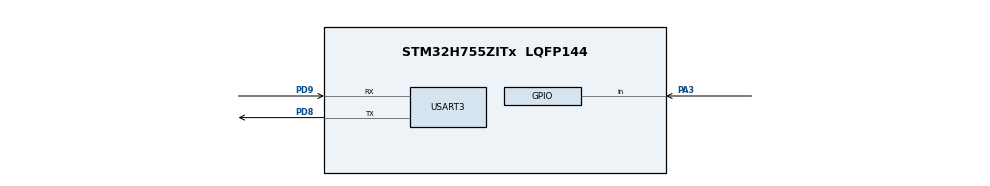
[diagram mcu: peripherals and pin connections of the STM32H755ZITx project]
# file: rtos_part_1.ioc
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CortexM4.IPs=FATFS_M4\:I,FREERTOS_M4\:I,IWDG2\:I,RCC,WWDG2\:I,DMA,BDMA,MDMA,NVIC2\:I,ETH,DEBUG,PDM2PCM_M4\:I,PWR,RESMGR_UTILITY,SYS_M4\:I,USB_DEVICE_M4\:I,USB_HOST_M4\:I,CORTEX_M4\:I,GPIO,OPENAMP_M4\:I,VREFBUF,NUCLEO-H755ZI-Q
CortexM7.IPs=FATFS_M7\:I,FREERTOS_M7\:I,IWDG1\:I,RCC\:I,WWDG1\:I,DMA\:I,BDMA\:I,MDMA\:I,NVIC1\:I,ETH\:I,USB_OTG_FS\:I,USB_OTG_FS1\:I,SYS\:I,CORTEX_M7\:I,DEBUG\:I,PDM2PCM_M7\:I,PWR\:I,RESMGR_UTILITY\:I,USB_DEVICE_M7\:I,USB_HOST_M7\:I,GPIO\:I,OPENAMP_M7\:I,VREFBUF\:I,NUCLEO-H755ZI-Q\:I,TIM6\:I,USART3\:I
CortexM7.Pins=PA3
FREERTOS_M7.Queues01=message_q,10,uint32_t,0,Dynamic,NULL,NULL
FREERTOS_M7.Tasks01=Task_1,24,128,Start_Task_1,Default,NULL,Dynamic,NULL,NULL;Task_2,24,128,Start_Task_2,Default,NULL,Dynamic,NULL,NULL;Task_3_Rx,32,512,Rx_task,Default,NULL,Dynamic,NULL,NULL
FREERTOS_M7.configUSE_NEWLIB_REENTRANT=1
Mcu.Family=STM32H7
Mcu.Name=STM32H755ZITx
Mcu.Package=LQFP144
NVIC1.PriorityGroup=NVIC_PRIORITYGROUP_4
NVIC1.TIM6_DAC_IRQn=true\:15\:0\:false\:false\:true\:false\:false\:true\:true
NVIC1.TimeBase=TIM6_DAC_IRQn
NVIC1.TimeBaseIP=TIM6
NVIC2.PriorityGroup=NVIC_PRIORITYGROUP_4
PA3.GPIO_PuPd=GPIO_PULLUP
PA3.PinAttribute=CortexM7
PA3.Signal=GPIO_Input
PD8.Mode=Asynchronous
PD8.PinAttribute=CortexM7
PD8.Signal=USART3_TX
PD9.Mode=Asynchronous
PD9.PinAttribute=CortexM7
PD9.Signal=USART3_RX
ProjectManager.HeapSize=M4-0x200,M7-0x200
ProjectManager.StackSize=M4-0x400,M7-0x400
ProjectManager.TargetToolchain=STM32CubeIDE
RCC.ADCFreq_Value=129000000
RCC.APB1Freq_Value=100000000
RCC.APB2Freq_Value=100000000
RCC.APB3Freq_Value=100000000
RCC.APB4Freq_Value=100000000
RCC.CortexFreq_Value=400000000
RCC.D1PPRE=RCC_APB3_DIV2
RCC.D2PPRE1=RCC_APB1_DIV2
RCC.D2PPRE2=RCC_APB2_DIV2
RCC.D3PPRE=RCC_APB4_DIV2
RCC.DIVM1=4
RCC.DIVN1=50
RCC.DIVQ1=5
RCC.HCLKFreq_Value=200000000
RCC.HPRE=RCC_HCLK_DIV2
RCC.PLL2FRACN=0
RCC.PLL3FRACN=0
RCC.PLLFRACN=0
RCC.SYSCLKFreq_VALUE=400000000
RCC.SYSCLKSource=RCC_SYSCLKSOURCE_PLLCLK
RCC.SupplySource=PWR_DIRECT_SMPS_SUPPLY
RCC.USBFreq_Value=160000000
USART3.VirtualMode-Asynchronous=VM_ASYNC
VP_FREERTOS_M7_VS_CMSIS_V2.Mode=CMSIS_V2
VP_SYS_M4_VS_Systick.Mode=SysTick
VP_SYS_VS_tim6.Mode=TIM6
board=NUCLEO-H755ZI-Q

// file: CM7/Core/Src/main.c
/* USER CODE BEGIN Header */
/**
  ******************************************************************************
  * @file           : main.c
  * @brief          : Main program body
  ******************************************************************************
  * @attention
  *
  * Copyright (c) 2026 STMicroelectronics.
  * All rights reserved.
  *
  * This software is licensed under terms that can be found in the LICENSE file
  * in the root directory of this software component.
  * If no LICENSE file comes with this software, it is provided AS-IS.
  *
  ******************************************************************************
  */
/* USER CODE END Header */
#include "main.h"
#include "FreeRTOS.h"
#include "cmsis_os2.h"
#include "Stdio.h"

/* USER CODE BEGIN PD */

/* DUAL_CORE_BOOT_SYNC_SEQUENCE: Define for dual core boot synchronization    */
/*                             demonstration code based on hardware semaphore */
/* This define is present in both CM7/CM4 projects                            */
/* To comment when developping/debugging on a single core                     */
#define DUAL_CORE_BOOT_SYNC_SEQUENCE

#if defined(DUAL_CORE_BOOT_SYNC_SEQUENCE)
#ifndef HSEM_ID_0
#define HSEM_ID_0 (0U) /* HW semaphore 0*/
#endif
#endif /* DUAL_CORE_BOOT_SYNC_SEQUENCE */

/* USER CODE END PD */

UART_HandleTypeDef huart3;

/* Definitions for Task_1 */
osThreadId_t Task_1Handle;
const osThreadAttr_t Task_1_attributes = {
  .name = "Task_1",
  .stack_size = 128 * 4,
  .priority = (osPriority_t) osPriorityNormal,
};
/* Definitions for Task_2 */
osThreadId_t Task_2Handle;
const osThreadAttr_t Task_2_attributes = {
  .name = "Task_2",
  .stack_size = 128 * 4,
  .priority = (osPriority_t) osPriorityNormal,
};
/* Definitions for Task_3_Rx */
osThreadId_t Task_3_RxHandle;
const osThreadAttr_t Task_3_Rx_attributes = {
  .name = "Task_3_Rx",
  .stack_size = 512 * 4,
  .priority = (osPriority_t) osPriorityAboveNormal,
};
/* Definitions for message_q */
osMessageQueueId_t message_qHandle;
const osMessageQueueAttr_t message_q_attributes = {
  .name = "message_q"
};

void SystemClock_Config(void);
static void MX_GPIO_Init(void);
static void MX_USART3_UART_Init(void);
void Start_Task_1(void *argument);
void Start_Task_2(void *argument);
void Rx_task(void *argument);

/* USER CODE BEGIN 0 */
typedef struct {
	uint32_t timestamp;
	uint32_t event_id;
}message_q_t;
int _io_putchar(uint8_t ch){
	HAL_UART_Transmit(&huart3,&ch, 1, HAL_MAX_DELAY);
	return ch;
}
 int _write(int file, char *ptr, int len)
{
  (void)file;
  int DataIdx;

  for (DataIdx = 0; DataIdx < len; DataIdx++)
  {
	  _io_putchar(*ptr++);
  }
  return len;
}

/* USER CODE END 0 */

int main(void)
{

/* USER CODE BEGIN Boot_Mode_Sequence_0 */
#if defined(DUAL_CORE_BOOT_SYNC_SEQUENCE)
  int32_t timeout;
#endif /* DUAL_CORE_BOOT_SYNC_SEQUENCE */
/* USER CODE END Boot_Mode_Sequence_0 */

/* USER CODE BEGIN Boot_Mode_Sequence_1 */
#if defined(DUAL_CORE_BOOT_SYNC_SEQUENCE)
  /* Wait until CPU2 boots and enters in stop mode or timeout*/
  timeout = 0xFFFF;
  while((__HAL_RCC_GET_FLAG(RCC_FLAG_D2CKRDY) != RESET) && (timeout-- > 0));
  if ( timeout < 0 )
  {
  Error_Handler();
  }
#endif /* DUAL_CORE_BOOT_SYNC_SEQUENCE */
/* USER CODE END Boot_Mode_Sequence_1 */
  /* MCU Configuration--------------------------------------------------------*/

  /* Reset of all peripherals, Initializes the Flash interface and the Systick. */
  HAL_Init();

  /* Configure the system clock */
  SystemClock_Config();
/* USER CODE BEGIN Boot_Mode_Sequence_2 */
#if defined(DUAL_CORE_BOOT_SYNC_SEQUENCE)
/* When system initialization is finished, Cortex-M7 will release Cortex-M4 by means of
HSEM notification */
/*HW semaphore Clock enable*/
__HAL_RCC_HSEM_CLK_ENABLE();
/*Take HSEM */
HAL_HSEM_FastTake(HSEM_ID_0);
/*Release HSEM in order to notify the CPU2(CM4)*/
HAL_HSEM_Release(HSEM_ID_0,0);
/* wait until CPU2 wakes up from stop mode */
timeout = 0xFFFF;
while((__HAL_RCC_GET_FLAG(RCC_FLAG_D2CKRDY) == RESET) && (timeout-- > 0));
if ( timeout < 0 )
{
Error_Handler();
}
#endif /* DUAL_CORE_BOOT_SYNC_SEQUENCE */
/* USER CODE END Boot_Mode_Sequence_2 */

  /* Initialize all configured peripherals */
  MX_GPIO_Init();
  MX_USART3_UART_Init();

  /* Init scheduler */
  osKernelInitialize();

  /* Create the queue(s) */
  /* creation of message_q */
  message_qHandle = osMessageQueueNew (10, sizeof(message_q_t), &message_q_attributes);

  /* Create the thread(s) */
  /* creation of Task_1 */
  Task_1Handle = osThreadNew(Start_Task_1, NULL, &Task_1_attributes);

  /* creation of Task_2 */
  Task_2Handle = osThreadNew(Start_Task_2, NULL, &Task_2_attributes);

  /* creation of Task_3_Rx */
  Task_3_RxHandle = osThreadNew(Rx_task, NULL, &Task_3_Rx_attributes);

  /* Start scheduler */
  osKernelStart();

  /* We should never get here as control is now taken by the scheduler */

  /* Infinite loop */
  while (1)
  {

  }
}

void SystemClock_Config(void)
{
  RCC_OscInitTypeDef RCC_OscInitStruct = {0};
  RCC_ClkInitTypeDef RCC_ClkInitStruct = {0};

  /** Supply configuration update enable
  */
  HAL_PWREx_ConfigSupply(PWR_DIRECT_SMPS_SUPPLY);

  /** Configure the main internal regulator output voltage
  */
  __HAL_PWR_VOLTAGESCALING_CONFIG(PWR_REGULATOR_VOLTAGE_SCALE1);

  while(!__HAL_PWR_GET_FLAG(PWR_FLAG_VOSRDY)) {}

  /** Initializes the RCC Oscillators according to the specified parameters
  * in the RCC_OscInitTypeDef structure.
  */
  RCC_OscInitStruct.OscillatorType = RCC_OSCILLATORTYPE_HSI;
  RCC_OscInitStruct.HSIState = RCC_HSI_DIV1;
  RCC_OscInitStruct.HSICalibrationValue = RCC_HSICALIBRATION_DEFAULT;
  RCC_OscInitStruct.PLL.PLLState = RCC_PLL_ON;
  RCC_OscInitStruct.PLL.PLLSource = RCC_PLLSOURCE_HSI;
  RCC_OscInitStruct.PLL.PLLM = 4;
  RCC_OscInitStruct.PLL.PLLN = 50;
  RCC_OscInitStruct.PLL.PLLP = 2;
  RCC_OscInitStruct.PLL.PLLQ = 5;
  RCC_OscInitStruct.PLL.PLLR = 2;
  RCC_OscInitStruct.PLL.PLLRGE = RCC_PLL1VCIRANGE_3;
  RCC_OscInitStruct.PLL.PLLVCOSEL = RCC_PLL1VCOWIDE;
  RCC_OscInitStruct.PLL.PLLFRACN = 0;
  if (HAL_RCC_OscConfig(&RCC_OscInitStruct) != HAL_OK)
  {
    Error_Handler();
  }

  /** Initializes the CPU, AHB and APB buses clocks
  */
  RCC_ClkInitStruct.ClockType = RCC_CLOCKTYPE_HCLK|RCC_CLOCKTYPE_SYSCLK
                              |RCC_CLOCKTYPE_PCLK1|RCC_CLOCKTYPE_PCLK2
                              |RCC_CLOCKTYPE_D3PCLK1|RCC_CLOCKTYPE_D1PCLK1;
  RCC_ClkInitStruct.SYSCLKSource = RCC_SYSCLKSOURCE_PLLCLK;
  RCC_ClkInitStruct.SYSCLKDivider = RCC_SYSCLK_DIV1;
  RCC_ClkInitStruct.AHBCLKDivider = RCC_HCLK_DIV2;
  RCC_ClkInitStruct.APB3CLKDivider = RCC_APB3_DIV2;
  RCC_ClkInitStruct.APB1CLKDivider = RCC_APB1_DIV2;
  RCC_ClkInitStruct.APB2CLKDivider = RCC_APB2_DIV2;
  RCC_ClkInitStruct.APB4CLKDivider = RCC_APB4_DIV2;

  if (HAL_RCC_ClockConfig(&RCC_ClkInitStruct, FLASH_LATENCY_2) != HAL_OK)
  {
    Error_Handler();
  }
}

static void MX_USART3_UART_Init(void)
{

  huart3.Instance = USART3;
  huart3.Init.BaudRate = 115200;
  huart3.Init.WordLength = UART_WORDLENGTH_8B;
  huart3.Init.StopBits = UART_STOPBITS_1;
  huart3.Init.Parity = UART_PARITY_NONE;
  huart3.Init.Mode = UART_MODE_TX_RX;
  huart3.Init.HwFlowCtl = UART_HWCONTROL_NONE;
  huart3.Init.OverSampling = UART_OVERSAMPLING_16;
  huart3.Init.OneBitSampling = UART_ONE_BIT_SAMPLE_DISABLE;
  huart3.Init.ClockPrescaler = UART_PRESCALER_DIV1;
  huart3.AdvancedInit.AdvFeatureInit = UART_ADVFEATURE_NO_INIT;
  if (HAL_UART_Init(&huart3) != HAL_OK)
  {
    Error_Handler();
  }
  if (HAL_UARTEx_SetTxFifoThreshold(&huart3, UART_TXFIFO_THRESHOLD_1_8) != HAL_OK)
  {
    Error_Handler();
  }
  if (HAL_UARTEx_SetRxFifoThreshold(&huart3, UART_RXFIFO_THRESHOLD_1_8) != HAL_OK)
  {
    Error_Handler();
  }
  if (HAL_UARTEx_DisableFifoMode(&huart3) != HAL_OK)
  {
    Error_Handler();
  }

}

static void MX_GPIO_Init(void)
{
  GPIO_InitTypeDef GPIO_InitStruct = {0};

  /* GPIO Ports Clock Enable */
  __HAL_RCC_GPIOA_CLK_ENABLE();
  __HAL_RCC_GPIOD_CLK_ENABLE();

  /*Configure GPIO pin : PA3 */
  GPIO_InitStruct.Pin = GPIO_PIN_3;
  GPIO_InitStruct.Mode = GPIO_MODE_INPUT;
  GPIO_InitStruct.Pull = GPIO_PULLUP;
  HAL_GPIO_Init(GPIOA, &GPIO_InitStruct);

}

void Start_Task_1(void *argument)
{
  /* USER CODE BEGIN 5 */
  /* Infinite loop */

	 message_q_t msg;
  for(;;)
  {

	 if(HAL_GPIO_ReadPin(GPIOA, GPIO_PIN_3)==0){
		 msg.event_id=0x01;
		 msg.timestamp=HAL_GetTick();
		 osMessageQueuePut(message_qHandle, &msg,0,0);
		 osDelay(200);
	 }
	 osDelay(20);

  }
  /* USER CODE END 5 */
}

void Start_Task_2(void *argument)
{
  /* USER CODE BEGIN Start_Task_2 */
  /* Infinite loop */
	message_q_t msg;
  for(;;)
  {
	  msg.event_id=0x02;
		 msg.timestamp=HAL_GetTick()/1000;
		 osMessageQueuePut(message_qHandle, &msg,0,0);
		 osDelay(1000);
	 }
	 osDelay(20);

  /* USER CODE END Start_Task_2 */
}

void Rx_task(void *argument)
{
  /* USER CODE BEGIN Rx_task */
  /* Infinite loop */
	message_q_t msg;
  for(;;)
  {
if(osMessageQueueGet(message_qHandle, &msg,0, osWaitForever)==osOK){
	printf("event id %d and event stamp %lu\r\n",msg.event_id,msg.timestamp);

}
  }
  /* USER CODE END Rx_task */
}

void HAL_TIM_PeriodElapsedCallback(TIM_HandleTypeDef *htim)
{
  if (htim->Instance == TIM6)
  {
    HAL_IncTick();
  }
}

void Error_Handler(void)
{
  __disable_irq();
  while (1)
  {
  }
}
